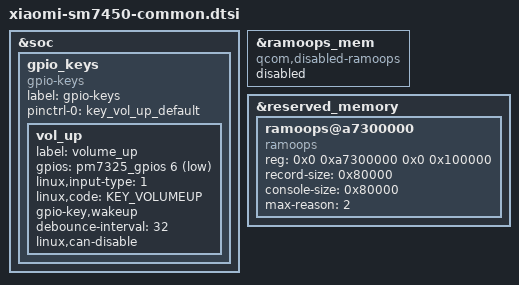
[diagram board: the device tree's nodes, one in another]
&soc {
	gpio_keys {
		compatible = "gpio-keys";
		label = "gpio-keys";

		pinctrl-names = "default";
		pinctrl-0 = <&key_vol_up_default>;

		vol_up {
			label = "volume_up";
			gpios = <&pm7325_gpios 6 GPIO_ACTIVE_LOW>;
			linux,input-type = <1>;
			linux,code = <KEY_VOLUMEUP>;
			gpio-key,wakeup;
			debounce-interval = <32>;
			linux,can-disable;
		};
	};
};

&ramoops_mem {
	compatible = "qcom,disabled-ramoops";
	status = "disabled";
};

&reserved_memory {
	#address-cells = <2>;
	#size-cells = <2>;
	ranges;

	ramoops@a7300000 {
		compatible = "ramoops";
		reg = <0x0 0xa7300000 0x0 0x100000>;
		record-size = <0x80000>;
		console-size = <0x80000>;
		max-reason = <2>;
	};
};
